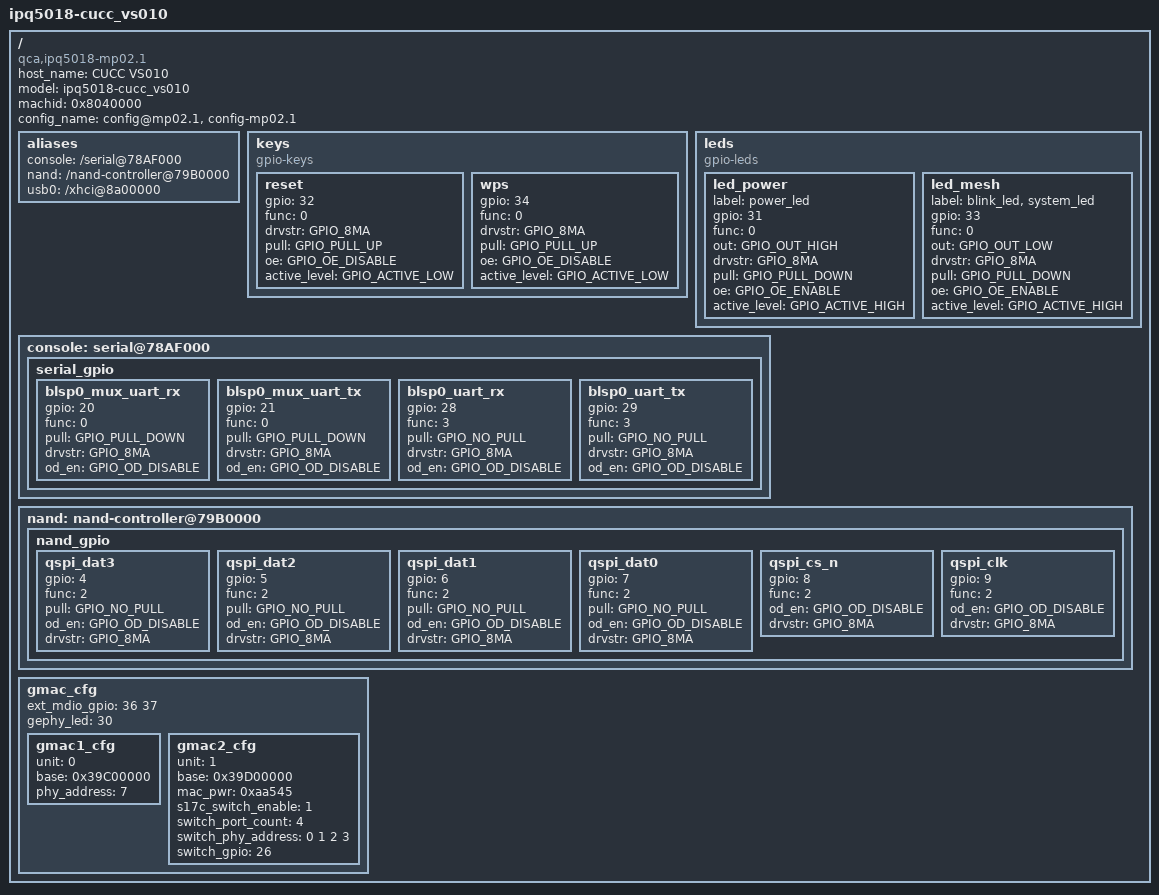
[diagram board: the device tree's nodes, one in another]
/*
 * Copyright (c) 2016-2020, The Linux Foundation. All rights reserved.
 *
 * This program is free software; you can redistribute it and/or modify
 * it under the terms of the GNU General Public License version 2 and
 * only version 2 as published by the Free Software Foundation.
 *
 * This program is distributed in the hope that it will be useful,
 * but WITHOUT ANY WARRANTY; without even the implied warranty of
 * MERCHANTABILITY or FITNESS FOR A PARTICULAR PURPOSE.  See the
 * GNU General Public License for more details.
 */

/dts-v1/;
#include "ipq5018-soc.dtsi"
/ {
	host_name = "CUCC VS010";
	model ="ipq5018-cucc_vs010";
	compatible = "qca,ipq5018-mp02.1", "qca,ipq5018";
	machid = <0x8040000>;
	config_name = "config@mp02.1", "config-mp02.1";

	aliases {
		console = "/serial@78AF000";
		nand = "/nand-controller@79B0000";
		usb0 = "/xhci@8a00000";
	};

    keys {
		compatible = "gpio-keys";

        reset {
            gpio = <32>;
            func = <0>;
            drvstr = <GPIO_8MA>;
            pull = <GPIO_PULL_UP>;
            oe = <GPIO_OE_DISABLE>;
			active_level = <GPIO_ACTIVE_LOW>;
        };

        wps {
            gpio = <34>;
            func = <0>;
            drvstr = <GPIO_8MA>;
            pull = <GPIO_PULL_UP>;
            oe = <GPIO_OE_DISABLE>;
			active_level = <GPIO_ACTIVE_LOW>;
        };
    };

    leds {
		compatible = "gpio-leds";

        led_power {
			label = "power_led";
            gpio = <31>;
            func = <0>;
            out = <GPIO_OUT_HIGH>;
            drvstr = <GPIO_8MA>;
            pull = <GPIO_PULL_DOWN>;
            oe = <GPIO_OE_ENABLE>;
            active_level = <GPIO_ACTIVE_HIGH>;
        };

        led_mesh {
			label = "blink_led", "system_led";
            gpio = <33>;
            func = <0>;
            out = <GPIO_OUT_LOW>;
            drvstr = <GPIO_8MA>;
            pull = <GPIO_PULL_DOWN>;
            oe = <GPIO_OE_ENABLE>;
            active_level = <GPIO_ACTIVE_HIGH>;
        };
    };

	console: serial@78AF000 {
		status = "ok";
		serial_gpio {
			blsp0_mux_uart_rx {
				gpio = <20>;
				func = <0>;
				pull = <GPIO_PULL_DOWN>;
				drvstr = <GPIO_8MA>;
				od_en = <GPIO_OD_DISABLE>;
			};
			blsp0_mux_uart_tx {
				gpio = <21>;
				func = <0>;
				pull = <GPIO_PULL_DOWN>;
				drvstr = <GPIO_8MA>;
				od_en = <GPIO_OD_DISABLE>;
			};
			blsp0_uart_rx {
				gpio = <28>;
				func = <3>;
				pull = <GPIO_NO_PULL>;
				drvstr = <GPIO_8MA>;
				od_en = <GPIO_OD_DISABLE>;
			};
			blsp0_uart_tx {
				gpio = <29>;
				func = <3>;
				pull = <GPIO_NO_PULL>;
				drvstr = <GPIO_8MA>;
				od_en = <GPIO_OD_DISABLE>;
			};
		};
	};

	nand: nand-controller@79B0000 {
		status = "okay";
		nand_gpio {
			qspi_dat3 {
				gpio = <4>;
				func = <2>;
				pull = <GPIO_NO_PULL>;
				od_en = <GPIO_OD_DISABLE>;
				drvstr = <GPIO_8MA>;
			};
			qspi_dat2 {
				gpio = <5>;
				func = <2>;
				pull = <GPIO_NO_PULL>;
				od_en = <GPIO_OD_DISABLE>;
				drvstr = <GPIO_8MA>;
			};
			qspi_dat1 {
				gpio = <6>;
				func = <2>;
				pull = <GPIO_NO_PULL>;
				od_en = <GPIO_OD_DISABLE>;
				drvstr = <GPIO_8MA>;
			};
			qspi_dat0 {
				gpio = <7>;
				func = <2>;
				pull = <GPIO_NO_PULL>;
				od_en = <GPIO_OD_DISABLE>;
				drvstr = <GPIO_8MA>;
			};
			qspi_cs_n {
				gpio = <8>;
				func = <2>;
				od_en = <GPIO_OD_DISABLE>;
				drvstr = <GPIO_8MA>;
			};
			qspi_clk {
				gpio = <9>;
				func = <2>;
				od_en = <GPIO_OD_DISABLE>;
				drvstr = <GPIO_8MA>;
			};
		};
	};

	gmac_cfg {
		ext_mdio_gpio = <36 37>;
		gephy_led = <30>;

		gmac1_cfg {
			unit = <0>;
			base = <0x39C00000>;
			phy_address = <7>;
		};
		gmac2_cfg {
			unit = <1>;
			base = <0x39D00000>;
			mac_pwr = <0xaa545>;
			s17c_switch_enable = <1>;
			switch_port_count = <4>;
			switch_phy_address = <0 1 2 3>;
			switch_gpio = <26>;
		};
	};
};
